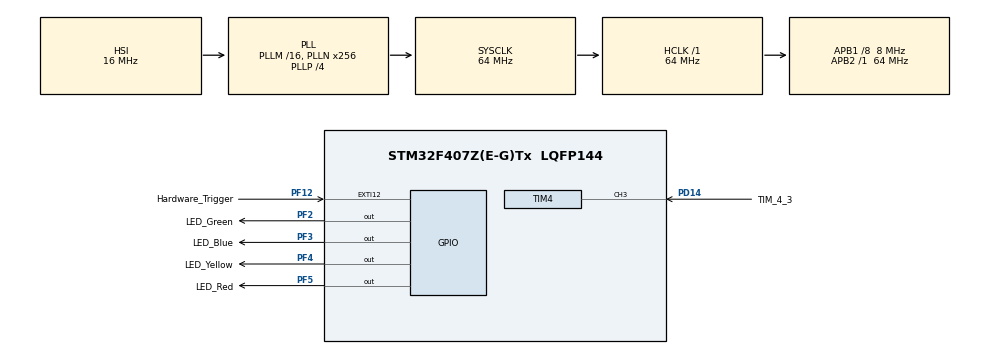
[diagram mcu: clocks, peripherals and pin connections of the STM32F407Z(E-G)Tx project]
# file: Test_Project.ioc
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Mcu.Family=STM32F4
Mcu.Name=STM32F407Z(E-G)Tx
Mcu.Package=LQFP144
NVIC.EXTI15_10_IRQn=true\:1\:0\:true\:false\:true\:true
NVIC.PriorityGroup=NVIC_PRIORITYGROUP_4
NVIC.TIM4_IRQn=true\:1\:0\:true\:false\:true\:true
PD14.GPIO_Label=TIM_4_3
PD14.GPIO_PuPd=GPIO_PULLDOWN
PD14.Signal=S_TIM4_CH3
PF12.GPIO_Label=Hardware_Trigger
PF12.GPIO_PuPd=GPIO_PULLDOWN
PF12.Signal=GPXTI12
PF2.GPIO_Label=LED_Green
PF2.GPIO_PuPd=GPIO_PULLDOWN
PF2.Signal=GPIO_Output
PF3.GPIO_Label=LED_Blue
PF3.GPIO_PuPd=GPIO_PULLDOWN
PF3.Signal=GPIO_Output
PF4.GPIO_Label=LED_Yellow
PF4.GPIO_PuPd=GPIO_PULLDOWN
PF4.Signal=GPIO_Output
PF5.GPIO_Label=LED_Red
PF5.GPIO_PuPd=GPIO_PULLDOWN
PF5.Signal=GPIO_Output
ProjectManager.HeapSize=0x200
ProjectManager.StackSize=0x400
ProjectManager.TargetToolchain=Makefile
RCC.48MHZClocksFreq_Value=64000000
RCC.AHBFreq_Value=64000000
RCC.APB1CLKDivider=RCC_HCLK_DIV8
RCC.APB1Freq_Value=8000000
RCC.APB1TimFreq_Value=16000000
RCC.APB2Freq_Value=64000000
RCC.APB2TimFreq_Value=64000000
RCC.CortexFreq_Value=64000000
RCC.HCLKFreq_Value=64000000
RCC.HSE_VALUE=25000000
RCC.HSI_VALUE=16000000
RCC.LSE_VALUE=32768
RCC.PLLN=256
RCC.PLLP=RCC_PLLP_DIV4
RCC.SYSCLKFreq_VALUE=64000000
RCC.SYSCLKSource=RCC_SYSCLKSOURCE_PLLCLK
RCC.VCOOutputFreq_Value=256000000
SH.S_TIM4_CH3.0=TIM4_CH3,Input_Capture3_from_TI3
TIM4.Channel-Input_Capture3_from_TI3=TIM_CHANNEL_3
TIM4.ICPolarity_CH3=TIM_INPUTCHANNELPOLARITY_BOTHEDGE
TIM4.Period=0xFFFF
TIM4.Prescaler=0
board=Test_Project

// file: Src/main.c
/**
  ******************************************************************************
  * File Name          : main.c
  * Description        : Main program body
  ******************************************************************************
  ** This notice applies to any and all portions of this file
  * that are not between comment pairs USER CODE BEGIN and
  * USER CODE END. Other portions of this file, whether
  * inserted by the user or by software development tools
  * are owned by their respective copyright owners.
  *
  * COPYRIGHT(c) 2017 STMicroelectronics
  *
  * Redistribution and use in source and binary forms, with or without modification,
  * are permitted provided that the following conditions are met:
  *   1. Redistributions of source code must retain the above copyright notice,
  *      this list of conditions and the following disclaimer.
  *   2. Redistributions in binary form must reproduce the above copyright notice,
  *      this list of conditions and the following disclaimer in the documentation
  *      and/or other materials provided with the distribution.
  *   3. Neither the name of STMicroelectronics nor the names of its contributors
  *      may be used to endorse or promote products derived from this software
  *      without specific prior written permission.
  *
  * THIS SOFTWARE IS PROVIDED BY THE COPYRIGHT HOLDERS AND CONTRIBUTORS "AS IS"
  * AND ANY EXPRESS OR IMPLIED WARRANTIES, INCLUDING, BUT NOT LIMITED TO, THE
  * IMPLIED WARRANTIES OF MERCHANTABILITY AND FITNESS FOR A PARTICULAR PURPOSE ARE
  * DISCLAIMED. IN NO EVENT SHALL THE COPYRIGHT HOLDER OR CONTRIBUTORS BE LIABLE
  * FOR ANY DIRECT, INDIRECT, INCIDENTAL, SPECIAL, EXEMPLARY, OR CONSEQUENTIAL
  * DAMAGES (INCLUDING, BUT NOT LIMITED TO, PROCUREMENT OF SUBSTITUTE GOODS OR
  * SERVICES; LOSS OF USE, DATA, OR PROFITS; OR BUSINESS INTERRUPTION) HOWEVER
  * CAUSED AND ON ANY THEORY OF LIABILITY, WHETHER IN CONTRACT, STRICT LIABILITY,
  * OR TORT (INCLUDING NEGLIGENCE OR OTHERWISE) ARISING IN ANY WAY OUT OF THE USE
  * OF THIS SOFTWARE, EVEN IF ADVISED OF THE POSSIBILITY OF SUCH DAMAGE.
  *
  ******************************************************************************
  */

#include "main.h"
#include "stm32f4xx_hal.h"

/* USER CODE BEGIN Includes */
unsigned char start_capture = 0;
/* USER CODE END Includes */

TIM_HandleTypeDef htim4;

/* USER CODE BEGIN PV */
/* Private variables ---------------------------------------------------------*/
volatile unsigned char uIRQ_Temp = 0;
/* volatile uint16_t uwDiffCapture = 0; */
volatile unsigned char uPulse_width_2T = 0;
volatile unsigned char uPulse_width_T = 0;
/* USER CODE END PV */

void SystemClock_Config(void);
static void MX_GPIO_Init(void);
static void MX_TIM4_Init(void);

/* USER CODE BEGIN PFP */
/* Private function prototypes -----------------------------------------------*/

/* USER CODE END PFP */

int main(void)
{

  /* MCU Configuration----------------------------------------------------------*/

  /* Reset of all peripherals, Initializes the Flash interface and the Systick. */
  HAL_Init();

  /* Configure the system clock */
  SystemClock_Config();

  /* Initialize all configured peripherals */
  MX_GPIO_Init();
  MX_TIM4_Init();

  /* USER CODE BEGIN 2 */
  while(start_capture == 0)
    {
    }

  /* Start TIM4, CH3 in IC Interrupt mode */
  if(HAL_TIM_IC_Start_IT(&htim4, TIM_CHANNEL_3) != HAL_OK)
    {
      _Error_Handler(__FILE__, __LINE__);
    }

  /* while(uPulse_width_2T == 0) */
  /*   { */
  /*     HAL_GPIO_TogglePin(LED_Red_GPIO_Port, LED_Red_Pin); */
  /*     HAL_Delay(250); */
  /*   } */
  HAL_GPIO_WritePin(LED_Red_GPIO_Port, LED_Red_Pin, GPIO_PIN_SET);

  while(uPulse_width_T == 0)
    {
      HAL_GPIO_TogglePin(LED_Blue_GPIO_Port, LED_Blue_Pin);
      HAL_Delay(250);
    }

  HAL_GPIO_WritePin(LED_Green_GPIO_Port, LED_Green_Pin, GPIO_PIN_SET);
  /* USER CODE END 2 */

  /* Infinite loop */
  while (1)
  {

  }

}

/** System Clock Configuration
*/
void SystemClock_Config(void)
{

  RCC_OscInitTypeDef RCC_OscInitStruct;
  RCC_ClkInitTypeDef RCC_ClkInitStruct;

    /**Configure the main internal regulator output voltage
    */
  __HAL_RCC_PWR_CLK_ENABLE();

  __HAL_PWR_VOLTAGESCALING_CONFIG(PWR_REGULATOR_VOLTAGE_SCALE1);

    /**Initializes the CPU, AHB and APB busses clocks
    */
  RCC_OscInitStruct.OscillatorType = RCC_OSCILLATORTYPE_HSI;
  RCC_OscInitStruct.HSIState = RCC_HSI_ON;
  RCC_OscInitStruct.HSICalibrationValue = 16;
  RCC_OscInitStruct.PLL.PLLState = RCC_PLL_ON;
  RCC_OscInitStruct.PLL.PLLSource = RCC_PLLSOURCE_HSI;
  RCC_OscInitStruct.PLL.PLLM = 16;
  RCC_OscInitStruct.PLL.PLLN = 256;
  RCC_OscInitStruct.PLL.PLLP = RCC_PLLP_DIV4;
  RCC_OscInitStruct.PLL.PLLQ = 4;
  if (HAL_RCC_OscConfig(&RCC_OscInitStruct) != HAL_OK)
  {
    _Error_Handler(__FILE__, __LINE__);
  }

    /**Initializes the CPU, AHB and APB busses clocks
    */
  RCC_ClkInitStruct.ClockType = RCC_CLOCKTYPE_HCLK|RCC_CLOCKTYPE_SYSCLK
                              |RCC_CLOCKTYPE_PCLK1|RCC_CLOCKTYPE_PCLK2;
  RCC_ClkInitStruct.SYSCLKSource = RCC_SYSCLKSOURCE_PLLCLK;
  RCC_ClkInitStruct.AHBCLKDivider = RCC_SYSCLK_DIV1;
  RCC_ClkInitStruct.APB1CLKDivider = RCC_HCLK_DIV8;
  RCC_ClkInitStruct.APB2CLKDivider = RCC_HCLK_DIV1;

  if (HAL_RCC_ClockConfig(&RCC_ClkInitStruct, FLASH_LATENCY_2) != HAL_OK)
  {
    _Error_Handler(__FILE__, __LINE__);
  }

    /**Configure the Systick interrupt time
    */
  HAL_SYSTICK_Config(HAL_RCC_GetHCLKFreq()/1000);

    /**Configure the Systick
    */
  HAL_SYSTICK_CLKSourceConfig(SYSTICK_CLKSOURCE_HCLK);

  /* SysTick_IRQn interrupt configuration */
  HAL_NVIC_SetPriority(SysTick_IRQn, 0, 0);
}

/* TIM4 init function */
static void MX_TIM4_Init(void)
{

  TIM_MasterConfigTypeDef sMasterConfig;
  TIM_IC_InitTypeDef sConfigIC;

  htim4.Instance = TIM4;
  htim4.Init.Prescaler = 0;
  htim4.Init.CounterMode = TIM_COUNTERMODE_UP;
  htim4.Init.Period = 0xFFFF;
  htim4.Init.ClockDivision = TIM_CLOCKDIVISION_DIV1;
  if (HAL_TIM_IC_Init(&htim4) != HAL_OK)
  {
    _Error_Handler(__FILE__, __LINE__);
  }

  sMasterConfig.MasterOutputTrigger = TIM_TRGO_RESET;
  sMasterConfig.MasterSlaveMode = TIM_MASTERSLAVEMODE_DISABLE;
  if (HAL_TIMEx_MasterConfigSynchronization(&htim4, &sMasterConfig) != HAL_OK)
  {
    _Error_Handler(__FILE__, __LINE__);
  }

  sConfigIC.ICPolarity = TIM_INPUTCHANNELPOLARITY_BOTHEDGE;
  sConfigIC.ICSelection = TIM_ICSELECTION_DIRECTTI;
  sConfigIC.ICPrescaler = TIM_ICPSC_DIV1;
  sConfigIC.ICFilter = 0;
  if (HAL_TIM_IC_ConfigChannel(&htim4, &sConfigIC, TIM_CHANNEL_3) != HAL_OK)
  {
    _Error_Handler(__FILE__, __LINE__);
  }

}

/** Configure pins as
        * Analog
        * Input
        * Output
        * EVENT_OUT
        * EXTI
*/
static void MX_GPIO_Init(void)
{

  GPIO_InitTypeDef GPIO_InitStruct;

  /* GPIO Ports Clock Enable */
  __HAL_RCC_GPIOF_CLK_ENABLE();
  __HAL_RCC_GPIOD_CLK_ENABLE();

  /*Configure GPIO pin Output Level */
  HAL_GPIO_WritePin(GPIOF, LED_Green_Pin|LED_Blue_Pin|LED_Yellow_Pin|LED_Red_Pin, GPIO_PIN_RESET);

  /*Configure GPIO pins : LED_Green_Pin LED_Blue_Pin LED_Yellow_Pin LED_Red_Pin */
  GPIO_InitStruct.Pin = LED_Green_Pin|LED_Blue_Pin|LED_Yellow_Pin|LED_Red_Pin;
  GPIO_InitStruct.Mode = GPIO_MODE_OUTPUT_PP;
  GPIO_InitStruct.Pull = GPIO_PULLDOWN;
  GPIO_InitStruct.Speed = GPIO_SPEED_FREQ_LOW;
  HAL_GPIO_Init(GPIOF, &GPIO_InitStruct);

  /*Configure GPIO pin : Hardware_Trigger_Pin */
  GPIO_InitStruct.Pin = Hardware_Trigger_Pin;
  GPIO_InitStruct.Mode = GPIO_MODE_IT_RISING;
  GPIO_InitStruct.Pull = GPIO_PULLDOWN;
  HAL_GPIO_Init(Hardware_Trigger_GPIO_Port, &GPIO_InitStruct);

  /* EXTI interrupt init*/
  HAL_NVIC_SetPriority(EXTI15_10_IRQn, 1, 0);
  HAL_NVIC_EnableIRQ(EXTI15_10_IRQn);

}

void _Error_Handler(char * file, int line)
{
  while(1)
  {
  }
}

/************************ (C) COPYRIGHT STMicroelectronics *****END OF FILE****/
